# STM32L052xx register map
File version: 1.0
Registers are 32-bit, read-write, reset 0x0 unless marked. A register's access mark holds for its fields unless they carry their own. Offsets are from the block's base; [hi:lo] are bit positions; {n}, {i} and the like mark numbered series.

## I2C2 — Inter-integrated Circuit Interface
Base 0x40005800
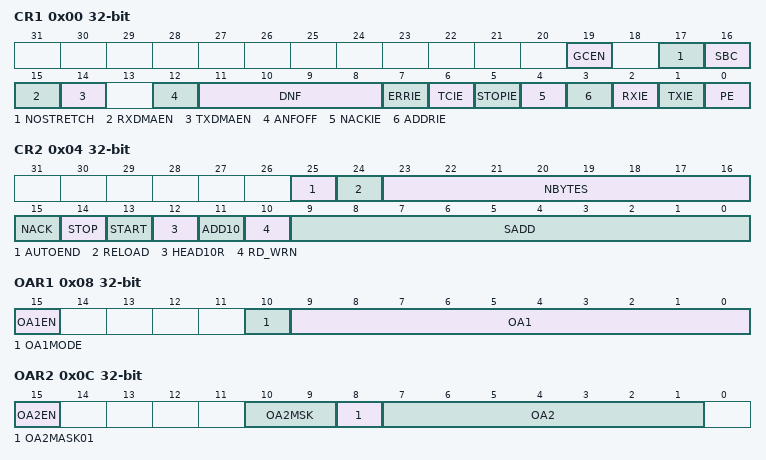
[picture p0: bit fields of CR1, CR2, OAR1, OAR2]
0x00 CR1 — I2C Control register 1
  [19] GCEN — General call enable
  [17] NOSTRETCH — Clock stretching disable
  [16] SBC — Slave byte control
  [15] RXDMAEN — DMA reception requests enable
  [14] TXDMAEN — DMA transmission requests enable
  [12] ANFOFF — Analog noise filter OFF
  [11:8] DNF — Digital noise filter
  [7] ERRIE — Errors interrupt enable
  [6] TCIE — Transfer complete interrupt enable
  [5] STOPIE — STOP detection interrupt enable
  [4] NACKIE — NACK received interrupt enable
  [3] ADDRIE — Address match interrupt enable
  [2] RXIE — RX interrupt enable
  [1] TXIE — TX interrupt enable
  [0] PE — Peripheral enable
0x04 CR2 — I2C Control register 2
  [25] AUTOEND — Automatic end mode (master mode)
  [24] RELOAD — NBYTES reload mode
  [23:16] NBYTES — Number of bytes
  [15] NACK — NACK generation (slave mode)
    0=ACK (ACK is sent after current received byte.); 1=NACK (NACK is sent after current received byte.)
  [14] STOP — STOP generation (master mode)
  [13] START — START generation
  [12] HEAD10R — 10-bit address header only read direction (master mode)
  [11] ADD10 — 10-bit addressing mode (master mode)
    0=MODE_7BIT (Master operates in 7-bit addressing mode.); 1=MODE_10BIT (Master operates in 10-bit addressing mode.)
  [10] RD_WRN — Transfer direction (master mode)
    0=WRITE (Master request a write transfer.); 1=READ (Master request a read transfer.)
  [9:0] SADD — Slave address (master mode)
0x08 OAR1 — I2C Own address 1 register
  [15] OA1EN — Own address 1 enable
  [10] OA1MODE — Own address 1 10-bit mode
  [9:0] OA1 — Interface own address 1
0x0C OAR2 — I2C Own address 2 register
  [15] OA2EN — Own address 2 enable
  [10:9] OA2MSK — Own address 2 masks
  [8] OA2MASK01 — OA2[1] is masked, Only OA2[7:2] are compared
  [7:1] OA2 — Interface own address 2
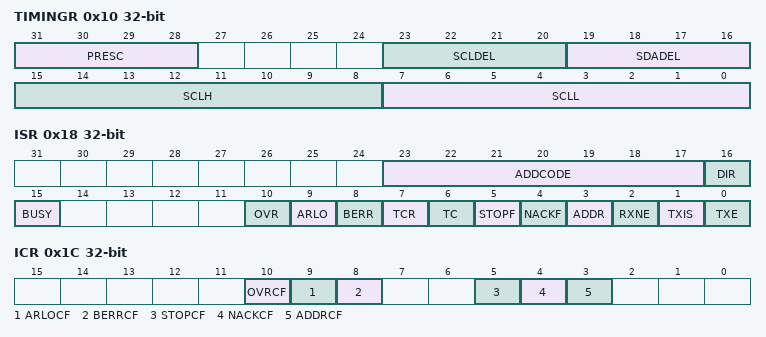
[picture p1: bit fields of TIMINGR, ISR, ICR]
0x10 TIMINGR — I2C Timing register
  [31:28] PRESC — Timings prescaler
  [23:20] SCLDEL — Data setup time
  [19:16] SDADEL — Data hold time
  [15:8] SCLH — SCL high period (master mode)
  [7:0] SCLL — SCL low period (master mode)
0x18 ISR — I2C Interrupt and status register
  [23:17] ADDCODE — Address match code (slave mode)
  [16] DIR — Transfer direction (slave mode)
    0=WRITE; 1=READ
  [15] BUSY — Bus busy
  [10] OVR — Overrun/Underrun
  [9] ARLO — Arbitration lost
  [8] BERR — Bus error
  [7] TCR — Transfer complete reload
  [6] TC — Transfer complete (master mode)
  [5] STOPF — STOP detection flag
  [4] NACKF — NACK received flag
  [3] ADDR — Address matched (slave mode)
  [2] RXNE — Receive data register not empty
  [1] TXIS — Transmit interrupt status
  [0] TXE — Transmit data register empty
0x1C ICR — I2C Interrupt clear register
  [10] OVRCF — Overrun/Underrun clear flag
  [9] ARLOCF — Arbitration lost clear flag
  [8] BERRCF — Bus error clear flag
  [5] STOPCF — STOP detection clear flag
  [4] NACKCF — NACK clear flag
  [3] ADDRCF — Address matched clear flag
0x24 RXDR — I2C Receive data register
  [7:0] RXDATA — 8-bit receive data
0x28 TXDR — I2C Transmit data register
  [7:0] TXDATA — 8-bit transmit data

## USB — Universal Serial Bus Full Speed Device
Base 0x40005C00
{0x0+4i} EP{i}R 16-bit (i=0..7) — USB Endpoint {i} register
0x40 CNTR 16-bit — Control register
0x44 ISTR 16-bit — Interrupt status register
0x48 FNR 16-bit — Frame number register
0x4C DADDR 16-bit — Device address register
0x50 BTABLE 16-bit — Buffer Table address register
0x54 LPMCSR 16-bit — LPM Control and Status register
0x58 BCDR 16-bit — Battery Charging detector register

## CRS — Clock Recovery System
Base 0x40006C00
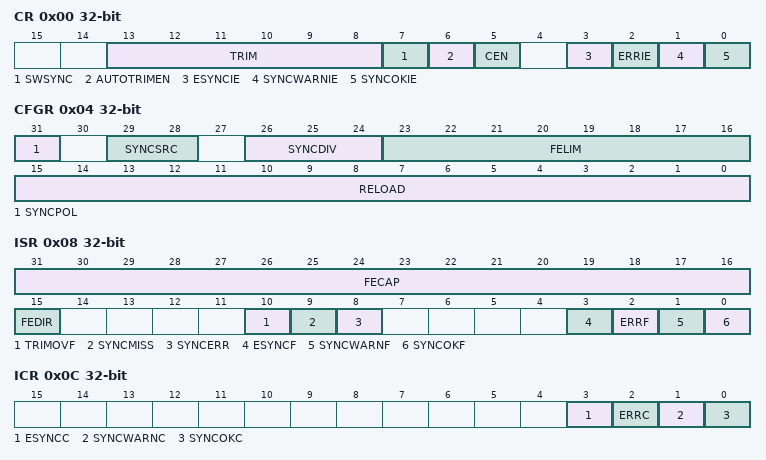
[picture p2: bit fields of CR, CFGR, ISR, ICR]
0x00 CR — CRS ccontrol register
  [13:8] TRIM, [7] SWSYNC, [6] AUTOTRIMEN, [5] CEN, [3] ESYNCIE, [2] ERRIE, [1] SYNCWARNIE, [0] SYNCOKIE
0x04 CFGR — CRS configuration register
  [31] SYNCPOL
    0=RISING (Synchro Active on rising edge (default)); 1=FALLING (Synchro Active on falling edge)
  [29:28] SYNCSRC
    0=GPIO (Synchro Signal source GPIO); 1=LSE (Synchro Signal source LSE); 2=USB (Synchro Signal source USB SOF (default))
  [26:24] SYNCDIV
    0=DIV_1 (Synchro Signal not divided (default)); 1=DIV_2 (Synchro Signal divided by 2); 2=DIV_4 (Synchro Signal divided by 4); 3=DIV_8 (Synchro Signal divided by 8); 4=DIV_16 (Synchro Signal divided by 16); 5=DIV_32 (Synchro Signal divided by 32); 6=DIV_64 (Synchro Signal divided by 64); 7=DIV_128 (Synchro Signal divided by 128)
  [23:16] FELIM
  [15:0] RELOAD
0x08 ISR — CRS interrupt and status register
  [31:16] FECAP
  [15] FEDIR
    0=UP (Upcounting direction, the actual frequency is above the target); 1=DOWN (Downcounting direction, the actual frequency is below the target)
  [10] TRIMOVF
  [9] SYNCMISS
  [8] SYNCERR
  [3] ESYNCF
  [2] ERRF
  [1] SYNCWARNF
  [0] SYNCOKF
0x0C ICR — CRS interrupt flag clear register
  [3] ESYNCC, [2] ERRC, [1] SYNCWARNC, [0] SYNCOKC
